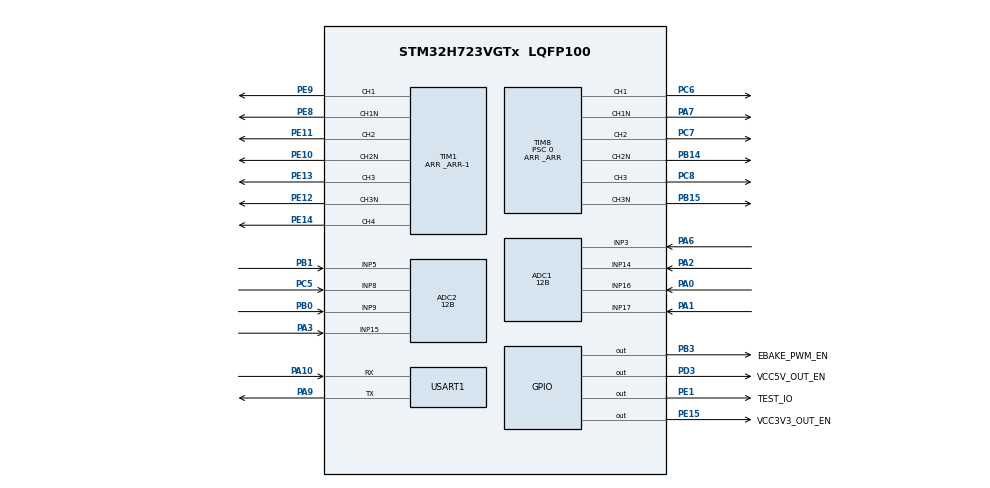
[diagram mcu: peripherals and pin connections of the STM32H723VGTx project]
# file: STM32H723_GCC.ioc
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ADC1.Channel-0\#ChannelRegularConversion=ADC_CHANNEL_3
ADC1.ClockPrescaler=ADC_CLOCK_ASYNC_DIV4
ADC1.ContinuousConvMode=ENABLE
ADC1.ConversionDataManagement=ADC_CONVERSIONDATA_DR
ADC1.EOCSelection=ADC_EOC_SEQ_CONV
ADC1.EnableInjectedConversion=ENABLE
ADC1.ExternalTrigConv=ADC_SOFTWARE_START
ADC1.ExternalTrigInjecConv=ADC_EXTERNALTRIGINJEC_T1_CC4
ADC1.InjNumberOfConversion=3
ADC1.InjectedChannel-11\#ChannelInjectedConversion=ADC_CHANNEL_14
ADC1.InjectedChannel-12\#ChannelInjectedConversion=ADC_CHANNEL_16
ADC1.InjectedChannel-13\#ChannelInjectedConversion=ADC_CHANNEL_17
ADC1.InjectedOffsetNumber-11\#ChannelInjectedConversion=ADC_OFFSET_NONE
ADC1.InjectedOffsetNumber-12\#ChannelInjectedConversion=ADC_OFFSET_NONE
ADC1.InjectedOffsetNumber-13\#ChannelInjectedConversion=ADC_OFFSET_NONE
ADC1.InjectedOffsetSaturation-11\#ChannelInjectedConversion=DISABLE
ADC1.InjectedOffsetSaturation-12\#ChannelInjectedConversion=DISABLE
ADC1.InjectedOffsetSaturation-13\#ChannelInjectedConversion=DISABLE
ADC1.InjectedRank-11\#ChannelInjectedConversion=1
ADC1.InjectedRank-12\#ChannelInjectedConversion=2
ADC1.InjectedRank-13\#ChannelInjectedConversion=3
ADC1.InjectedSamplingTime-11\#ChannelInjectedConversion=ADC_SAMPLETIME_1CYCLE_5
ADC1.InjectedSamplingTime-12\#ChannelInjectedConversion=ADC_SAMPLETIME_1CYCLE_5
ADC1.InjectedSamplingTime-13\#ChannelInjectedConversion=ADC_SAMPLETIME_1CYCLE_5
ADC1.LeftBitShift=ADC_LEFTBITSHIFT_NONE
ADC1.Mode=ADC_DUALMODE_INJECSIMULT
ADC1.NbrOfConversion=1
ADC1.NbrOfConversionFlag=1
ADC1.OffsetNumber-0\#ChannelRegularConversion=ADC_OFFSET_NONE
ADC1.OffsetSignedSaturation-0\#ChannelRegularConversion=DISABLE
ADC1.Overrun=ADC_OVR_DATA_OVERWRITTEN
ADC1.Rank-0\#ChannelRegularConversion=1
ADC1.Resolution=ADC_RESOLUTION_12B
ADC1.SamplingTime-0\#ChannelRegularConversion=ADC_SAMPLETIME_1CYCLE_5
ADC1.TwoSamplingDelay=ADC_TWOSAMPLINGDELAY_2CYCLES
ADC1.master=1
ADC2.Channel-0\#ChannelRegularConversion=ADC_CHANNEL_15
ADC2.ClockPrescaler=ADC_CLOCK_ASYNC_DIV4
ADC2.ConversionDataManagement=ADC_CONVERSIONDATA_DR
ADC2.EOCSelection=ADC_EOC_SEQ_CONV
ADC2.EnableInjectedConversion=ENABLE
ADC2.InjNumberOfConversion=3
ADC2.InjectedChannel-6\#ChannelInjectedConversion=ADC_CHANNEL_8
ADC2.InjectedChannel-7\#ChannelInjectedConversion=ADC_CHANNEL_9
ADC2.InjectedChannel-8\#ChannelInjectedConversion=ADC_CHANNEL_5
ADC2.InjectedOffsetNumber-6\#ChannelInjectedConversion=ADC_OFFSET_NONE
ADC2.InjectedOffsetNumber-7\#ChannelInjectedConversion=ADC_OFFSET_NONE
ADC2.InjectedOffsetNumber-8\#ChannelInjectedConversion=ADC_OFFSET_NONE
ADC2.InjectedOffsetSaturation-6\#ChannelInjectedConversion=DISABLE
ADC2.InjectedOffsetSaturation-7\#ChannelInjectedConversion=DISABLE
ADC2.InjectedOffsetSaturation-8\#ChannelInjectedConversion=DISABLE
ADC2.InjectedOffsetSignedSaturation-6\#ChannelInjectedConversion=DISABLE
ADC2.InjectedOffsetSignedSaturation-7\#ChannelInjectedConversion=DISABLE
ADC2.InjectedOffsetSignedSaturation-8\#ChannelInjectedConversion=DISABLE
ADC2.InjectedRank-6\#ChannelInjectedConversion=1
ADC2.InjectedRank-7\#ChannelInjectedConversion=2
ADC2.InjectedRank-8\#ChannelInjectedConversion=3
ADC2.InjectedSamplingTime-6\#ChannelInjectedConversion=ADC_SAMPLETIME_1CYCLE_5
ADC2.InjectedSamplingTime-7\#ChannelInjectedConversion=ADC_SAMPLETIME_1CYCLE_5
ADC2.InjectedSamplingTime-8\#ChannelInjectedConversion=ADC_SAMPLETIME_1CYCLE_5
ADC2.LeftBitShift=ADC_LEFTBITSHIFT_NONE
ADC2.Mode=ADC_DUALMODE_INJECSIMULT
ADC2.NbrOfConversion=1
ADC2.NbrOfConversionFlag=1
ADC2.OffsetNumber-0\#ChannelRegularConversion=ADC_OFFSET_NONE
ADC2.OffsetSignedSaturation-0\#ChannelRegularConversion=DISABLE
ADC2.Overrun=ADC_OVR_DATA_OVERWRITTEN
ADC2.Rank-0\#ChannelRegularConversion=1
ADC2.Resolution=ADC_RESOLUTION_12B
ADC2.SamplingTime-0\#ChannelRegularConversion=ADC_SAMPLETIME_1CYCLE_5
ADC2.TwoSamplingDelay=ADC_TWOSAMPLINGDELAY_2CYCLES
CORTEX_M7.BaseAddress_S-Cortex_Memory_Protection_Unit_Region1_Settings_S=0x30004000
CORTEX_M7.BaseAddress_Spec=0x30000000
CORTEX_M7.CPU_DCache=Disabled
CORTEX_M7.CPU_ICache=Enabled
CORTEX_M7.DisableExec_Spec=MPU_INSTRUCTION_ACCESS_ENABLE
CORTEX_M7.Enable_S-Cortex_Memory_Protection_Unit_Region1_Settings_S=MPU_REGION_ENABLE
CORTEX_M7.IsShareable_S-Cortex_Memory_Protection_Unit_Region1_Settings_S=MPU_ACCESS_SHAREABLE
CORTEX_M7.Size_S-Cortex_Memory_Protection_Unit_Region1_Settings_S=MPU_REGION_SIZE_16KB
CORTEX_M7.Size_Spec=MPU_REGION_SIZE_256B
CORTEX_M7.SubRegionDisable_Spec=0x00
CORTEX_M7.TypeExtField_S-Cortex_Memory_Protection_Unit_Region1_Settings_S=MPU_TEX_LEVEL1
CORTEX_M7.default_mode_Activation=0
Dma.Request0=USART1_TX
Dma.Request1=USART1_RX
Dma.USART1_RX.1.Direction=DMA_PERIPH_TO_MEMORY
Dma.USART1_RX.1.EventEnable=DISABLE
Dma.USART1_RX.1.FIFOMode=DMA_FIFOMODE_DISABLE
Dma.USART1_RX.1.Instance=DMA1_Stream1
Dma.USART1_RX.1.MemDataAlignment=DMA_MDATAALIGN_BYTE
Dma.USART1_RX.1.MemInc=DMA_MINC_ENABLE
Dma.USART1_RX.1.Mode=DMA_NORMAL
Dma.USART1_RX.1.PeriphDataAlignment=DMA_PDATAALIGN_BYTE
Dma.USART1_RX.1.PeriphInc=DMA_PINC_DISABLE
Dma.USART1_RX.1.Polarity=HAL_DMAMUX_REQ_GEN_RISING
Dma.USART1_RX.1.Priority=DMA_PRIORITY_LOW
Dma.USART1_RX.1.RequestNumber=1
Dma.USART1_RX.1.SignalID=NONE
Dma.USART1_RX.1.SyncEnable=DISABLE
Dma.USART1_RX.1.SyncPolarity=HAL_DMAMUX_SYNC_NO_EVENT
Dma.USART1_RX.1.SyncRequestNumber=1
Dma.USART1_RX.1.SyncSignalID=NONE
Dma.USART1_TX.0.Direction=DMA_MEMORY_TO_PERIPH
Dma.USART1_TX.0.EventEnable=DISABLE
Dma.USART1_TX.0.FIFOMode=DMA_FIFOMODE_DISABLE
Dma.USART1_TX.0.Instance=DMA1_Stream0
Dma.USART1_TX.0.MemDataAlignment=DMA_MDATAALIGN_BYTE
Dma.USART1_TX.0.MemInc=DMA_MINC_ENABLE
Dma.USART1_TX.0.Mode=DMA_NORMAL
Dma.USART1_TX.0.PeriphDataAlignment=DMA_PDATAALIGN_BYTE
Dma.USART1_TX.0.PeriphInc=DMA_PINC_DISABLE
Dma.USART1_TX.0.Polarity=HAL_DMAMUX_REQ_GEN_RISING
Dma.USART1_TX.0.Priority=DMA_PRIORITY_LOW
Dma.USART1_TX.0.RequestNumber=1
Dma.USART1_TX.0.SignalID=NONE
Dma.USART1_TX.0.SyncEnable=DISABLE
Dma.USART1_TX.0.SyncPolarity=HAL_DMAMUX_SYNC_NO_EVENT
Dma.USART1_TX.0.SyncRequestNumber=1
Dma.USART1_TX.0.SyncSignalID=NONE
Mcu.Family=STM32H7
Mcu.Name=STM32H723VGTx
Mcu.Package=LQFP100
Mcu.UserConstants=_ENCODERLINS,2500;_ARR,13750
NVIC.ADC_IRQn=true\:0\:0\:false\:false\:true\:true\:true\:true
NVIC.PriorityGroup=NVIC_PRIORITYGROUP_4
NVIC.USART1_IRQn=true\:2\:0\:true\:false\:true\:true\:true\:true
PA0.Mode=IN16-Single-Ended
PA0.Signal=ADC1_INP16
PA1.Mode=IN17-Single-Ended
PA1.Signal=ADC1_INP17
PA10.Mode=Asynchronous
PA10.Signal=USART1_RX
PA13(JTMS/SWDIO).Mode=Serial_Wire
PA13(JTMS/SWDIO).Signal=DEBUG_JTMS-SWDIO
PA14(JTCK/SWCLK).Mode=Serial_Wire
PA14(JTCK/SWCLK).Signal=DEBUG_JTCK-SWCLK
PA2.Signal=ADCx_INP14
PA3.Signal=ADCx_INP15
PA6.Signal=ADCx_INP3
PA7.Mode=PWM Generation1 CH1 CH1N
PA7.Signal=TIM8_CH1N
PA9.Mode=Asynchronous
PA9.Signal=USART1_TX
PB0.Signal=ADCx_INP9
PB1.Signal=ADCx_INP5
PB14.Mode=PWM Generation2 CH2 CH2N
PB14.Signal=TIM8_CH2N
PB15.Mode=PWM Generation3 CH3 CH3N
PB15.Signal=TIM8_CH3N
PB3(JTDO/TRACESWO).GPIO_Label=EBAKE_PWM_EN
PB3(JTDO/TRACESWO).Signal=GPIO_Output
PC5.Signal=ADCx_INP8
PC6.Signal=S_TIM8_CH1
PC7.Signal=S_TIM8_CH2
PC8.Signal=S_TIM8_CH3
PD3.GPIO_Label=VCC5V_OUT_EN
PD3.Signal=GPIO_Output
PE1.GPIO_Label=TEST_IO
PE1.Signal=GPIO_Output
PE10.Mode=PWM Generation2 CH2 CH2N
PE10.Signal=TIM1_CH2N
PE11.Signal=S_TIM1_CH2
PE12.Mode=PWM Generation3 CH3 CH3N
PE12.Signal=TIM1_CH3N
PE13.Signal=S_TIM1_CH3
PE14.Signal=S_TIM1_CH4
PE15.GPIO_Label=VCC3V3_OUT_EN
PE15.Signal=GPIO_Output
PE8.Mode=PWM Generation1 CH1 CH1N
PE8.Signal=TIM1_CH1N
PE9.Signal=S_TIM1_CH1
PH0-OSC_IN.Mode=HSE-External-Oscillator
PH0-OSC_IN.Signal=RCC_OSC_IN
PH1-OSC_OUT.Mode=HSE-External-Oscillator
PH1-OSC_OUT.Signal=RCC_OSC_OUT
ProjectManager.HeapSize=0x200
ProjectManager.StackSize=0x400
ProjectManager.TargetToolchain=Makefile
RCC.ADCFreq_Value=64000000
RCC.APB1Freq_Value=137500000
RCC.APB2Freq_Value=137500000
RCC.APB3Freq_Value=137500000
RCC.APB4Freq_Value=137500000
RCC.CortexFreq_Value=550000000
RCC.D1PPRE=RCC_APB3_DIV2
RCC.D2PPRE1=RCC_APB1_DIV2
RCC.D2PPRE2=RCC_APB2_DIV2
RCC.D3PPRE=RCC_APB4_DIV2
RCC.DIVM1=4
RCC.DIVM2=4
RCC.DIVN1=34
RCC.DIVN2=12
RCC.DIVP1=1
RCC.DIVP2=3
RCC.DIVQ2=8
RCC.FDCANCLockSelection=RCC_FDCANCLKSOURCE_PLL2
RCC.HCLKFreq_Value=275000000
RCC.HPRE=RCC_HCLK_DIV2
RCC.HSE_VALUE=12000000
RCC.PLL2FRACN=0
RCC.PLL3FRACN=0
RCC.PLLFRACN=3072
RCC.SYSCLKFreq_VALUE=550000000
RCC.SYSCLKSource=RCC_SYSCLKSOURCE_PLLCLK
RCC.USART16CLockSelection=RCC_USART16910CLKSOURCE_HSI
RCC.USBFreq_Value=275000000
SH.ADCx_INP14.0=ADC1_INP14,IN14-Single-Ended
SH.ADCx_INP15.0=ADC2_INP15,IN15-Single-Ended
SH.ADCx_INP3.0=ADC1_INP3,IN3-Single-Ended
SH.ADCx_INP5.0=ADC2_INP5,IN5-Single-Ended
SH.ADCx_INP8.0=ADC2_INP8,IN8-Single-Ended
SH.ADCx_INP9.0=ADC2_INP9,IN9-Single-Ended
SH.S_TIM1_CH1.0=TIM1_CH1,PWM Generation1 CH1 CH1N
SH.S_TIM1_CH2.0=TIM1_CH2,PWM Generation2 CH2 CH2N
SH.S_TIM1_CH3.0=TIM1_CH3,PWM Generation3 CH3 CH3N
SH.S_TIM1_CH4.0=TIM1_CH4,PWM Generation4 CH4
SH.S_TIM8_CH1.0=TIM8_CH1,PWM Generation1 CH1 CH1N
SH.S_TIM8_CH2.0=TIM8_CH2,PWM Generation2 CH2 CH2N
SH.S_TIM8_CH3.0=TIM8_CH3,PWM Generation3 CH3 CH3N
TIM1.Channel-PWM\ Generation1\ CH1\ CH1N=TIM_CHANNEL_1
TIM1.Channel-PWM\ Generation2\ CH2\ CH2N=TIM_CHANNEL_2
TIM1.Channel-PWM\ Generation3\ CH3\ CH3N=TIM_CHANNEL_3
TIM1.Channel-PWM\ Generation4\ CH4=TIM_CHANNEL_4
TIM1.CounterMode=TIM_COUNTERMODE_CENTERALIGNED1
TIM1.DeadTime=120
TIM1.OCNPolarity_1=TIM_OCNPOLARITY_LOW
TIM1.OCNPolarity_2=TIM_OCNPOLARITY_LOW
TIM1.OCNPolarity_3=TIM_OCNPOLARITY_LOW
TIM1.Period=_ARR-1
TIM1.TIM_MasterOutputTrigger=TIM_TRGO_ENABLE
TIM1.TIM_MasterOutputTrigger2=TIM_TRGO2_OC4REF
TIM1.TIM_MasterSlaveMode=TIM_MASTERSLAVEMODE_ENABLE
TIM8.AutoReloadPreload=TIM_AUTORELOAD_PRELOAD_DISABLE
TIM8.Channel-PWM\ Generation1\ CH1\ CH1N=TIM_CHANNEL_1
TIM8.Channel-PWM\ Generation2\ CH2\ CH2N=TIM_CHANNEL_2
TIM8.Channel-PWM\ Generation3\ CH3\ CH3N=TIM_CHANNEL_3
TIM8.CounterMode=TIM_COUNTERMODE_CENTERALIGNED3
TIM8.DeadTime=120
TIM8.OCNPolarity_1=TIM_OCNPOLARITY_LOW
TIM8.OCNPolarity_2=TIM_OCNPOLARITY_LOW
TIM8.OCNPolarity_3=TIM_OCNPOLARITY_LOW
TIM8.Period=_ARR
TIM8.Prescaler=0
TIM8.Pulse-PWM\ Generation1\ CH1\ CH1N=_ARR/2
TIM8.Pulse-PWM\ Generation2\ CH2\ CH2N=_ARR/2
TIM8.Pulse-PWM\ Generation3\ CH3\ CH3N=_ARR/2
USART1.VirtualMode-Asynchronous=VM_ASYNC
VP_MEMORYMAP_VS_MEMORYMAP.Mode=CurAppReg
VP_TIM1_VS_ClockSourceINT.Mode=Internal
VP_TIM8_VS_ClockSourceITR.Mode=TriggerSource_ITR0
VP_TIM8_VS_ControllerModeTrigger.Mode=Trigger Mode
board=custom

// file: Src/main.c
/* USER CODE BEGIN Header */
/**
  ******************************************************************************
  * @file           : main.c
  * @brief          : Main program body
  ******************************************************************************
  * @attention
  *
  * Copyright (c) 2025 STMicroelectronics.
  * All rights reserved.
  *
  * This software is licensed under terms that can be found in the LICENSE file
  * in the root directory of this software component.
  * If no LICENSE file comes with this software, it is provided AS-IS.
  *
  ******************************************************************************
  */
/* USER CODE END Header */
#include "main.h"
#include "adc.h"
#include "dma.h"
#include "memorymap.h"
#include "tim.h"
#include "usart.h"
#include "gpio.h"

void SystemClock_Config(void);
void PeriphCommonClock_Config(void);

/* USER CODE BEGIN 0 */
void tim1_set_pwm(float _a, float _b, float _c);
void tim1_enable(void);
void adc_init_start(void);

volatile  uint32_t  i = 3800000;

/* USER CODE END 0 */

int main(void)
{

  /* Enable the CPU Cache */

  /* Enable I-Cache---------------------------------------------------------*/
  SCB_EnableICache();

  /* MCU Configuration--------------------------------------------------------*/

  /* Reset of all peripherals, Initializes the Flash interface and the Systick. */
  HAL_Init();

  /* Configure the system clock */
  SystemClock_Config();

  /* Configure the peripherals common clocks */
  PeriphCommonClock_Config();

  /* Initialize all configured peripherals */
  MX_GPIO_Init();
  MX_DMA_Init();
  MX_USART1_UART_Init();
  MX_TIM1_Init();
  MX_TIM8_Init();
  MX_ADC1_Init();
  MX_ADC2_Init();
  /* USER CODE BEGIN 2 */
  LL_GPIO_ResetOutputPin(TEST_IO_GPIO_Port, TEST_IO_Pin);
  printf("ll hello \r\n");
  tim1_enable();
  tim1_set_pwm(0.5f,0.5f,0.5f);
  LL_GPIO_SetOutputPin(TEST_IO_GPIO_Port, TEST_IO_Pin);

  adc1_start();

  /* USER CODE END 2 */

  /* Infinite loop */
  /* USER CODE BEGIN WHILE */
  while (1)
  {
    //
    /* USER CODE END WHILE */

    /* USER CODE BEGIN 3 */
    // printf("ll hello world\r\n");
    while(i--);
    i = 8000000;
  }
  /* USER CODE END 3 */
}

void SystemClock_Config(void)
{
  LL_FLASH_SetLatency(LL_FLASH_LATENCY_3);
  while(LL_FLASH_GetLatency()!= LL_FLASH_LATENCY_3)
  {
  }
  LL_PWR_ConfigSupply(LL_PWR_LDO_SUPPLY);
  LL_PWR_SetRegulVoltageScaling(LL_PWR_REGU_VOLTAGE_SCALE0);
  while (LL_PWR_IsActiveFlag_VOS() == 0)
  {
  }
  LL_RCC_HSI_Enable();

   /* Wait till HSI is ready */
  while(LL_RCC_HSI_IsReady() != 1)
  {

  }
  LL_RCC_HSI_SetCalibTrimming(64);
  LL_RCC_HSI_SetDivider(LL_RCC_HSI_DIV1);
  LL_RCC_PLL_SetSource(LL_RCC_PLLSOURCE_HSI);
  LL_RCC_PLL1P_Enable();
  LL_RCC_PLL1R_Enable();
  LL_RCC_PLL1_SetVCOInputRange(LL_RCC_PLLINPUTRANGE_8_16);
  LL_RCC_PLL1_SetVCOOutputRange(LL_RCC_PLLVCORANGE_WIDE);
  LL_RCC_PLL1_SetM(4);
  LL_RCC_PLL1_SetN(34);
  LL_RCC_PLL1_SetP(1);
  LL_RCC_PLL1_SetQ(2);
  LL_RCC_PLL1_SetR(2);
  LL_RCC_PLL1_SetFRACN(3072);
  LL_RCC_PLL1FRACN_Enable();
  LL_RCC_PLL1_Enable();

   /* Wait till PLL is ready */
  while(LL_RCC_PLL1_IsReady() != 1)
  {
  }

   /* Intermediate AHB prescaler 2 when target frequency clock is higher than 80 MHz */
   LL_RCC_SetAHBPrescaler(LL_RCC_AHB_DIV_2);

  LL_RCC_SetSysClkSource(LL_RCC_SYS_CLKSOURCE_PLL1);

   /* Wait till System clock is ready */
  while(LL_RCC_GetSysClkSource() != LL_RCC_SYS_CLKSOURCE_STATUS_PLL1)
  {

  }
  LL_RCC_SetSysPrescaler(LL_RCC_SYSCLK_DIV_1);
  LL_RCC_SetAHBPrescaler(LL_RCC_AHB_DIV_2);
  LL_RCC_SetAPB1Prescaler(LL_RCC_APB1_DIV_2);
  LL_RCC_SetAPB2Prescaler(LL_RCC_APB2_DIV_2);
  LL_RCC_SetAPB3Prescaler(LL_RCC_APB3_DIV_2);
  LL_RCC_SetAPB4Prescaler(LL_RCC_APB4_DIV_2);
  LL_SetSystemCoreClock(550000000);

   /* Update the time base */
  if (HAL_InitTick (TICK_INT_PRIORITY) != HAL_OK)
  {
    Error_Handler();
  }
}

void PeriphCommonClock_Config(void)
{
  LL_RCC_PLL2P_Enable();
  LL_RCC_PLL2_SetVCOInputRange(LL_RCC_PLLINPUTRANGE_8_16);
  LL_RCC_PLL2_SetVCOOutputRange(LL_RCC_PLLVCORANGE_WIDE);
  LL_RCC_PLL2_SetM(4);
  LL_RCC_PLL2_SetN(12);
  LL_RCC_PLL2_SetP(3);
  LL_RCC_PLL2_SetQ(8);
  LL_RCC_PLL2_SetR(2);
  LL_RCC_PLL2_Enable();

   /* Wait till PLL is ready */
  while(LL_RCC_PLL2_IsReady() != 1)
  {
  }

}

void Error_Handler(void)
{
  __disable_irq();
  while (1)
  {
  }
}
